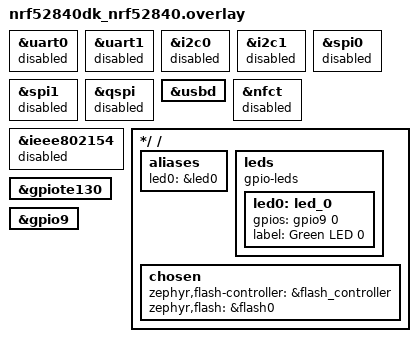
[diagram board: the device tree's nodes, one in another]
/*
/* Disable unused peripherals to save power. */
&uart0 { status = "disabled"; };
&uart1 { status = "disabled"; };
&i2c0 { status = "disabled"; };
&i2c1 { status = "disabled"; };
&spi0 { status = "disabled"; };
&spi1 { status = "disabled"; };
&qspi { status = "disabled"; };
&usbd { status = "disabled"; };
&nfct { status = "disabled"; };
&ieee802154 { status = "disabled"; };
*/

/ {
	aliases {
		led0 = &led0;
	};

	leds {
		compatible = "gpio-leds";

		led0: led_0 {
			gpios = <&gpio9 0 GPIO_ACTIVE_HIGH>;
			label = "Green LED 0";
		};
	};

    chosen {
        zephyr,flash-controller = &flash_controller;
        zephyr,flash = &flash0;
    };
};

/* Enable USB CDC ACM console. */
&usbd { status = "okay"; };

&gpiote130 {
	status = "okay";
};

&gpio9 {
	status = "okay";
};
